# nrf9120_mlm1_modem register map
Vendor: Nordic Semiconductor; Series: nrf91; File version: 1
CPU: CM4 r0p1, little endian, MPU, no FPU, 3 interrupt priority bits
Registers are 32-bit, read-write, reset 0x0 unless marked. A register's access mark holds for its fields unless they carry their own. Offsets are from the block's base; [hi:lo] are bit positions; {n}, {i} and the like mark numbered series; 'fields as' and 'values as' point back to an identical list.

## SNOW — Snow 3G Security IP
Base 0x40043000
0x00 TASKS_STARTGATHER wo — Start input DMA
  [0] TASKS_STARTGATHER
    1=Trigger task
0x04 TASKS_STOPGATHER wo — Stop input DMA
  [0] TASKS_STOPGATHER
    1=Trigger task
0x08 TASKS_STARTSCATTER wo — Start output DMA
  [0] TASKS_STARTSCATTER
    1=Trigger task
0x0C TASKS_STOPSCATTER wo — Stop output DMA
  [0] TASKS_STOPSCATTER
    1=Trigger task
0x10 TASKS_INITIALIZESNOW3G wo — New keys (and IV) ready to be used, reset keybytes, ivbytes
  [0] TASKS_INITIALIZESNOW3G
    1=Trigger task
0x14 TASKS_STARTOPERATION wo — Start cipher / MAC calculation depending on MODE
  [0] TASKS_STARTOPERATION
    1=Trigger task
0x18 TASKS_FINALIZEMAC wo — Finalize MAC calculation
  [0] TASKS_FINALIZEMAC
    1=Trigger task
0x1C TASKS_RESET wo — Stop all transfers and crypto operations (initialize)
  [0] TASKS_RESET
    1=Trigger task
0x70 TaskZeroPenalty_PCP_1 wo — TaskZeroPenalty register for PCP 1
  [0] ZeroTask
    1=ZeroTask (Set Zero Penalty)
0x74 TaskFullPenalty_PCP_1 wo — TaskFullPenalty register for PCP 1
  [0] FullTask
    1=FullTask (Set Full Penalty)
0x78 TaskZeroPenalty_PCP_0 wo — TaskZeroPenalty register for PCP 0
  [0] ZeroTask
    1=ZeroTask (Set Zero Penalty)
0x7C TaskFullPenalty_PCP_0 wo — TaskFullPenalty register for PCP 0
  [0] FullTask
    1=FullTask (Set Full Penalty)
0x100 EVENTS_GATHERSTARTED — Input DMA started
  [0] EVENTS_GATHERSTARTED
    0=NotGenerated (Event not generated); 1=Generated (Event generated)
0x104 EVENTS_GATHERDONE — Input DMA done
  [0] EVENTS_GATHERDONE
    values as EVENTS_GATHERSTARTED.EVENTS_GATHERSTARTED
0x108 EVENTS_SCATTERSTARTED — Output DMA started
  [0] EVENTS_SCATTERSTARTED
    values as EVENTS_GATHERSTARTED.EVENTS_GATHERSTARTED
0x10C EVENTS_SCATTERDONE — Output DMA done
  [0] EVENTS_SCATTERDONE
    values as EVENTS_GATHERSTARTED.EVENTS_GATHERSTARTED
0x110 EVENTS_IVREADY — IV received (ivbytes == 16)
  [0] EVENTS_IVREADY
    values as EVENTS_GATHERSTARTED.EVENTS_GATHERSTARTED
0x114 EVENTS_SNOW3GINITIALIZED — New keys and IV taken into use
  [0] EVENTS_SNOW3GINITIALIZED
    values as EVENTS_GATHERSTARTED.EVENTS_GATHERSTARTED
0x118 EVENTS_MESSAGEREADY — LENGTH == 0
  [0] EVENTS_MESSAGEREADY
    values as EVENTS_GATHERSTARTED.EVENTS_GATHERSTARTED
0x11C EVENTS_MACREADY — MAC calculated
  [0] EVENTS_MACREADY
    values as EVENTS_GATHERSTARTED.EVENTS_GATHERSTARTED
0x120 EVENTS_RESETTED — Resetted (all transfers and crypto operations stopped)
  [0] EVENTS_RESETTED
    values as EVENTS_GATHERSTARTED.EVENTS_GATHERSTARTED
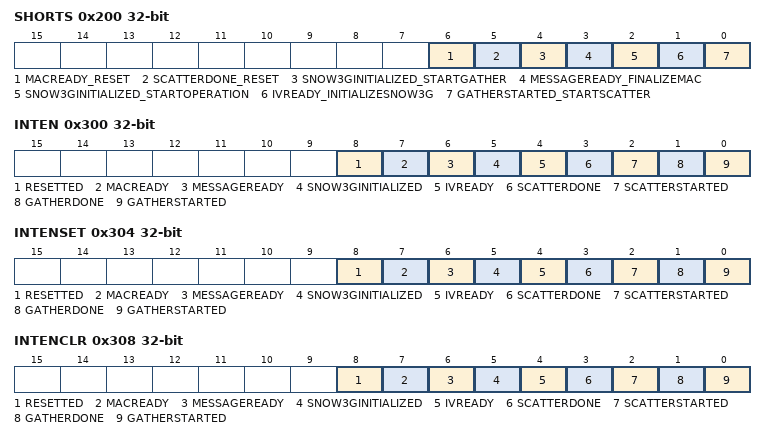
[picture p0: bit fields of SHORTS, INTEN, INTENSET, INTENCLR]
0x200 SHORTS — Shortcuts between local events and tasks
  [all] fields
    0=Disabled (Disable shortcut); 1=Enabled (Enable shortcut)
  [6] MACREADY_RESET — Shortcut between event MACREADY and task RESET
  [5] SCATTERDONE_RESET — Shortcut between event SCATTERDONE and task RESET
  [4] SNOW3GINITIALIZED_STARTGATHER — Shortcut between event SNOW3GINITIALIZED and task STARTGATHER
  [3] MESSAGEREADY_FINALIZEMAC — Shortcut between event MESSAGEREADY and task FINALIZEMAC
  [2] SNOW3GINITIALIZED_STARTOPERATION — Shortcut between event SNOW3GINITIALIZED and task STARTOPERATION
  [1] IVREADY_INITIALIZESNOW3G — Shortcut between event IVREADY and task INITIALIZESNOW3G
  [0] GATHERSTARTED_STARTSCATTER — Shortcut between event GATHERSTARTED and task STARTSCATTER
0x300 INTEN — Enable or disable interrupt
  [all] fields
    0=Disabled; 1=Enabled
  [8] RESETTED — Enable or disable interrupt for event RESETTED
  [7] MACREADY — Enable or disable interrupt for event MACREADY
  [6] MESSAGEREADY — Enable or disable interrupt for event MESSAGEREADY
  [5] SNOW3GINITIALIZED — Enable or disable interrupt for event SNOW3GINITIALIZED
  [4] IVREADY — Enable or disable interrupt for event IVREADY
  [3] SCATTERDONE — Enable or disable interrupt for event SCATTERDONE
  [2] SCATTERSTARTED — Enable or disable interrupt for event SCATTERSTARTED
  [1] GATHERDONE — Enable or disable interrupt for event GATHERDONE
  [0] GATHERSTARTED — Enable or disable interrupt for event GATHERSTARTED
0x304 INTENSET — Enable interrupt
  [all] fields
    on read: 0=Disabled (Read: Disabled); 1=Enabled (Read: Enabled) | on write: 1=Set (Enable)
  [8] RESETTED — Write '1' to enable interrupt for event RESETTED
  [7] MACREADY — Write '1' to enable interrupt for event MACREADY
  [6] MESSAGEREADY — Write '1' to enable interrupt for event MESSAGEREADY
  [5] SNOW3GINITIALIZED — Write '1' to enable interrupt for event SNOW3GINITIALIZED
  [4] IVREADY — Write '1' to enable interrupt for event IVREADY
  [3] SCATTERDONE — Write '1' to enable interrupt for event SCATTERDONE
  [2] SCATTERSTARTED — Write '1' to enable interrupt for event SCATTERSTARTED
  [1] GATHERDONE — Write '1' to enable interrupt for event GATHERDONE
  [0] GATHERSTARTED — Write '1' to enable interrupt for event GATHERSTARTED
0x308 INTENCLR — Disable interrupt
  [all] fields
    on read: 0=Disabled (Read: Disabled); 1=Enabled (Read: Enabled) | on write: 1=Clear (Disable)
  [8] RESETTED — Write '1' to disable interrupt for event RESETTED
  [7] MACREADY — Write '1' to disable interrupt for event MACREADY
  [6] MESSAGEREADY — Write '1' to disable interrupt for event MESSAGEREADY
  [5] SNOW3GINITIALIZED — Write '1' to disable interrupt for event SNOW3GINITIALIZED
  [4] IVREADY — Write '1' to disable interrupt for event IVREADY
  [3] SCATTERDONE — Write '1' to disable interrupt for event SCATTERDONE
  [2] SCATTERSTARTED — Write '1' to disable interrupt for event SCATTERSTARTED
  [1] GATHERDONE — Write '1' to disable interrupt for event GATHERDONE
  [0] GATHERSTARTED — Write '1' to disable interrupt for event GATHERSTARTED
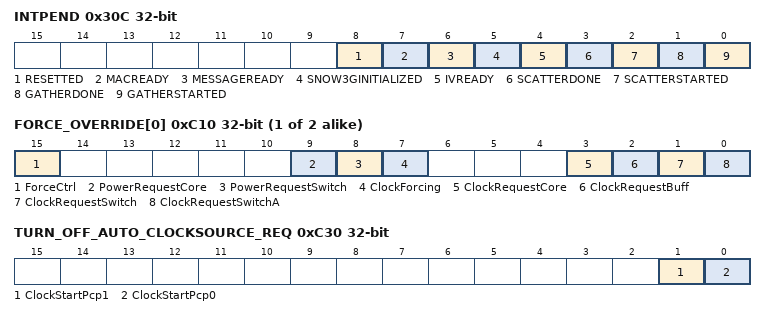
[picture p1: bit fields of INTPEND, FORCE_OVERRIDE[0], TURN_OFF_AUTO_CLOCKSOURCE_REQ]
0x30C INTPEND ro — Pending interrupts
  [all] fields
    on read: 0=NotPending (Read: Not pending); 1=Pending (Read: Pending)
  [8] RESETTED — Read pending status of interrupt for event RESETTED
  [7] MACREADY — Read pending status of interrupt for event MACREADY
  [6] MESSAGEREADY — Read pending status of interrupt for event MESSAGEREADY
  [5] SNOW3GINITIALIZED — Read pending status of interrupt for event SNOW3GINITIALIZED
  [4] IVREADY — Read pending status of interrupt for event IVREADY
  [3] SCATTERDONE — Read pending status of interrupt for event SCATTERDONE
  [2] SCATTERSTARTED — Read pending status of interrupt for event SCATTERSTARTED
  [1] GATHERDONE — Read pending status of interrupt for event GATHERDONE
  [0] GATHERSTARTED — Read pending status of interrupt for event GATHERSTARTED
0x400 LENGTH — Keystream length in bits (Cipher), message length in bits (MAC)
  [31:0] LENGTH — Stream/message length
0x404 MODE — Mode select
  [0] MODE — Mode select.
    0=CIPHER (Data cipher mode); 1=MAC (MAC mode.)
0x600 MAC ro — Message Authentication Code.
  [31:0] MAC — Calculated MAC.
0x800 INJOBPTR — Input job pointer
0x900 OUTJOBPTR — Output job pointer
{0xC00+4i} PENALTY_REG[{i}] (i=0..1) — Description collection: Penalty register for PCP n
  [1:0] Auto — Penalty Level
    0=Full ((Auto 0) Full penalty)); 1=Semi0 ((Auto 1) Semi (power on, clock off)); 2=Semi1 ((Auto 2) Semi (power on, clock core on, clock buffer off)); 3=Zero ((Auto 3) Zero penalty)
{0xC10+4i} FORCE_OVERRIDE[{i}] (i=0..1) — Description collection: Force override register for PCP n
  [15] ForceCtrl
    0=Disable (all forcing disabled); 1=Enable (all forcing enabled)
  [9] PowerRequestCore
    0=zero (powerRequest.core = 0); 1=one (powerRequest.core = 1)
  [8] PowerRequestSwitch
    0=zero (powerRequest.switch = 0); 1=one (powerRequest.switch = 1)
  [7] ClockForcing
    0=disable (All clock forcing disabled); 1=enable (All clock forcing enabled)
  [3] ClockRequestCore
    0=zero (clockRequest.core = 0); 1=one (clockRequest.core = 1)
  [2] ClockRequestBuff
    0=zero (clockRequest.buff = 0); 1=one (clockRequest.buff = 1)
  [1] ClockRequestSwitch
    0=zero (clockRequest.switch = 0); 1=one (clockRequest.switch = 1)
  [0] ClockRequestSwitchA
    0=zero (clockRequest.switch_a = 0); 1=one (clockRequest.switch_a = 1)
0xC30 TURN_OFF_AUTO_CLOCKSOURCE_REQ — Turn of the automatic clock request.
  [1] ClockStartPcp1
    0=normal_on (normal clock start for PCP 1); 1=normal_off (turn off normal clock start for PCP 1)
  [0] ClockStartPcp0
    0=normal_on (normal clock start for PCP 0); 1=normal_off (turn off normal clock start for PCP 0)
